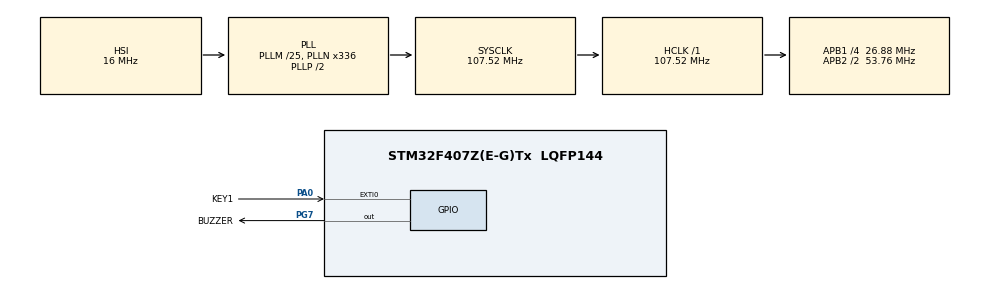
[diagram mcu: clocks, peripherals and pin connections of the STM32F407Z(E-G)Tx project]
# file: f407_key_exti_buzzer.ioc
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Mcu.Family=STM32F4
Mcu.Name=STM32F407Z(E-G)Tx
Mcu.Package=LQFP144
NVIC.EXTI0_IRQn=true\:5\:0\:true\:false\:true\:true\:true\:true
NVIC.PriorityGroup=NVIC_PRIORITYGROUP_4
PA0-WKUP.GPIO_Label=KEY1
PA0-WKUP.Signal=GPXTI0
PA13.Mode=Serial_Wire
PA13.Signal=SYS_JTMS-SWDIO
PA14.Mode=Serial_Wire
PA14.Signal=SYS_JTCK-SWCLK
PG7.GPIO_Label=BUZZER
PG7.Signal=GPIO_Output
PH0-OSC_IN.Mode=HSE-External-Oscillator
PH0-OSC_IN.Signal=RCC_OSC_IN
PH1-OSC_OUT.Mode=HSE-External-Oscillator
PH1-OSC_OUT.Signal=RCC_OSC_OUT
ProjectManager.HeapSize=0x200
ProjectManager.StackSize=0x400
ProjectManager.TargetToolchain=CMake
RCC.48MHZClocksFreq_Value=53760000
RCC.AHBFreq_Value=107520000
RCC.APB1CLKDivider=RCC_HCLK_DIV4
RCC.APB1Freq_Value=26880000
RCC.APB1TimFreq_Value=53760000
RCC.APB2CLKDivider=RCC_HCLK_DIV2
RCC.APB2Freq_Value=53760000
RCC.APB2TimFreq_Value=107520000
RCC.CortexFreq_Value=107520000
RCC.HCLKFreq_Value=107520000
RCC.HSE_VALUE=25000000
RCC.HSI_VALUE=16000000
RCC.LSE_VALUE=32768
RCC.PLLM=25
RCC.PLLN=336
RCC.SYSCLKFreq_VALUE=107520000
RCC.SYSCLKSource=RCC_SYSCLKSOURCE_PLLCLK
RCC.VCOOutputFreq_Value=215040000
board=custom

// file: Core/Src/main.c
/* USER CODE BEGIN Header */
/**
  ******************************************************************************
  * @file           : main.c
  * @brief          : Main program body
  ******************************************************************************
  * @attention
  *
  * Copyright (c) 2026 STMicroelectronics.
  * All rights reserved.
  *
  * This software is licensed under terms that can be found in the LICENSE file
  * in the root directory of this software component.
  * If no LICENSE file comes with this software, it is provided AS-IS.
  *
  ******************************************************************************
  */
/* USER CODE END Header */
#include "main.h"

/* USER CODE BEGIN PD */
#define KEY_DEBOUNCE_MS      50U
#define BUZZER_DURATION_MS   200U
/* USER CODE END PD */

/* USER CODE BEGIN PV */
/* 由中断函数设置，由主循环处理，因此必须使用volatile */
static volatile uint8_t key1_press_event = 0U;

/* 保存最近一次有效中断时间，用于软件消抖 */
static volatile uint32_t key1_last_irq_ms = 0U;

/* 蜂鸣器当前状态和开始鸣叫时间 */
static uint8_t buzzer_on = 0U;
static uint32_t buzzer_start_ms = 0U;
/* USER CODE END PV */

void SystemClock_Config(void);
static void MX_GPIO_Init(void);
/* USER CODE BEGIN PFP */
static void Buzzer_Set(uint8_t on);
static void Buzzer_Start(uint32_t now);
static void Buzzer_Update(uint32_t now);
/* USER CODE END PFP */

int main(void)
{

  /* MCU Configuration--------------------------------------------------------*/

  /* Reset of all peripherals, Initializes the Flash interface and the Systick. */
  HAL_Init();

  /* Configure the system clock */
  SystemClock_Config();

  /* Initialize all configured peripherals */
  MX_GPIO_Init();
  /* USER CODE BEGIN 2 */
  /* 启动时确保蜂鸣器关闭 */
  Buzzer_Set(0U);
  /* USER CODE END 2 */

  /* Infinite loop */
  /* USER CODE BEGIN WHILE */
  /* USER CODE BEGIN WHILE */
while (1)
{
  /* USER CODE END WHILE */

  /* USER CODE BEGIN 3 */

  uint32_t now = HAL_GetTick();

  /*
   * 中断函数只产生事件。
   * 真正的蜂鸣器控制放在主循环中完成。
   */
  if (key1_press_event != 0U)
  {
    key1_press_event = 0U;
    Buzzer_Start(now);
  }

  /*
   * 非阻塞检查蜂鸣器是否已经响满200ms。
   * 这里没有使用HAL_Delay。
   */
  Buzzer_Update(now);
}
/* USER CODE END 3 */
  /* USER CODE END 3 */
}

void SystemClock_Config(void)
{
  RCC_OscInitTypeDef RCC_OscInitStruct = {0};
  RCC_ClkInitTypeDef RCC_ClkInitStruct = {0};

  /** Configure the main internal regulator output voltage
  */
  __HAL_RCC_PWR_CLK_ENABLE();
  __HAL_PWR_VOLTAGESCALING_CONFIG(PWR_REGULATOR_VOLTAGE_SCALE1);

  /** Initializes the RCC Oscillators according to the specified parameters
  * in the RCC_OscInitTypeDef structure.
  */
  RCC_OscInitStruct.OscillatorType = RCC_OSCILLATORTYPE_HSI;
  RCC_OscInitStruct.HSIState = RCC_HSI_ON;
  RCC_OscInitStruct.HSICalibrationValue = RCC_HSICALIBRATION_DEFAULT;
  RCC_OscInitStruct.PLL.PLLState = RCC_PLL_ON;
  RCC_OscInitStruct.PLL.PLLSource = RCC_PLLSOURCE_HSI;
  RCC_OscInitStruct.PLL.PLLM = 25;
  RCC_OscInitStruct.PLL.PLLN = 336;
  RCC_OscInitStruct.PLL.PLLP = RCC_PLLP_DIV2;
  RCC_OscInitStruct.PLL.PLLQ = 4;
  if (HAL_RCC_OscConfig(&RCC_OscInitStruct) != HAL_OK)
  {
    Error_Handler();
  }

  /** Initializes the CPU, AHB and APB buses clocks
  */
  RCC_ClkInitStruct.ClockType = RCC_CLOCKTYPE_HCLK|RCC_CLOCKTYPE_SYSCLK
                              |RCC_CLOCKTYPE_PCLK1|RCC_CLOCKTYPE_PCLK2;
  RCC_ClkInitStruct.SYSCLKSource = RCC_SYSCLKSOURCE_PLLCLK;
  RCC_ClkInitStruct.AHBCLKDivider = RCC_SYSCLK_DIV1;
  RCC_ClkInitStruct.APB1CLKDivider = RCC_HCLK_DIV4;
  RCC_ClkInitStruct.APB2CLKDivider = RCC_HCLK_DIV2;

  if (HAL_RCC_ClockConfig(&RCC_ClkInitStruct, FLASH_LATENCY_3) != HAL_OK)
  {
    Error_Handler();
  }
}

static void MX_GPIO_Init(void)
{
  GPIO_InitTypeDef GPIO_InitStruct = {0};

  /* GPIO Ports Clock Enable */
  __HAL_RCC_GPIOH_CLK_ENABLE();
  __HAL_RCC_GPIOA_CLK_ENABLE();
  __HAL_RCC_GPIOG_CLK_ENABLE();

  /*Configure GPIO pin Output Level */
  HAL_GPIO_WritePin(BUZZER_GPIO_Port, BUZZER_Pin, GPIO_PIN_RESET);

  /*Configure GPIO pin : KEY1_Pin */
  GPIO_InitStruct.Pin = KEY1_Pin;
  GPIO_InitStruct.Mode = GPIO_MODE_IT_RISING;
  GPIO_InitStruct.Pull = GPIO_NOPULL;
  HAL_GPIO_Init(KEY1_GPIO_Port, &GPIO_InitStruct);

  /*Configure GPIO pin : BUZZER_Pin */
  GPIO_InitStruct.Pin = BUZZER_Pin;
  GPIO_InitStruct.Mode = GPIO_MODE_OUTPUT_PP;
  GPIO_InitStruct.Pull = GPIO_NOPULL;
  GPIO_InitStruct.Speed = GPIO_SPEED_FREQ_LOW;
  HAL_GPIO_Init(BUZZER_GPIO_Port, &GPIO_InitStruct);

  /* EXTI interrupt init*/
  HAL_NVIC_SetPriority(EXTI0_IRQn, 5, 0);
  HAL_NVIC_EnableIRQ(EXTI0_IRQn);

}

/* USER CODE BEGIN 4 */
/**
 * @brief GPIO外部中断回调函数
 * @param GPIO_Pin 产生中断的引脚编号
 */
void HAL_GPIO_EXTI_Callback(uint16_t GPIO_Pin)
{
  if (GPIO_Pin == KEY1_Pin)
  {
    uint32_t now = HAL_GetTick();

    /*
     * 两次有效事件至少间隔50ms。
     * 防止机械抖动产生多次中断。
     */
    if ((uint32_t)(now - key1_last_irq_ms) >= KEY_DEBOUNCE_MS)
    {
      key1_last_irq_ms = now;

      /*
       * 中断函数只设置事件标志。
       * 不在中断函数中控制复杂逻辑，也不使用HAL_Delay。
       */
      key1_press_event = 1U;
    }
  }
}

/**
 * @brief 控制板载蜂鸣器
 * @param on 1：响；0：关闭
 */
static void Buzzer_Set(uint8_t on)
{
  HAL_GPIO_WritePin(
      BUZZER_GPIO_Port,
      BUZZER_Pin,
      (on != 0U) ? GPIO_PIN_SET : GPIO_PIN_RESET);
}

/**
 * @brief 开始一次蜂鸣
 */
static void Buzzer_Start(uint32_t now)
{
  buzzer_on = 1U;
  buzzer_start_ms = now;
  Buzzer_Set(1U);
}

/**
 * @brief 非阻塞更新蜂鸣器状态
 */
static void Buzzer_Update(uint32_t now)
{
  if ((buzzer_on != 0U) &&
      ((uint32_t)(now - buzzer_start_ms) >= BUZZER_DURATION_MS))
  {
    buzzer_on = 0U;
    Buzzer_Set(0U);
  }
}
/* USER CODE END 4 */

void Error_Handler(void)
{
  __disable_irq();
  while (1)
  {
  }
}
